VERSION "2027-draft-2026-10-23"

NS_ :

BS_:

BU_: BPS ElconInterface
VAL_TABLE_ EnableDisable 1 "Enabled" 0 "Disabled" ;
VAL_TABLE_ OnOff 1 "On" 0 "Off" ;
VAL_TABLE_ FaultState 1 "Fault" 0 "OK" ;
VAL_TABLE_ WarningState 1 "Warning" 0 "NoWarning" ;
VAL_TABLE_ DeviceStatus 2 "Waiting" 1 "Fault" 0 "OK" ;
VAL_TABLE_ Permission 1 "Allowed" 0 "NotAllowed" ;
VAL_TABLE_ Connection 1 "Connected" 0 "Disconnected" ;
VAL_TABLE_ BalancingMode 2 "Manual" 1 "Automatic" 0 "Off" ;
VAL_TABLE_ BalancingState 4 "BlockedOrFault" 3 "Complete" 2 "Paused" 1 "Balancing" 0 "Off" ;
VAL_TABLE_ BalancingBlockReason 7 "Other" 6 "BPSFault" 5 "Communication" 4 "VehicleState" 3 "CellVoltage" 2 "ChipTemperature" 1 "CellTemperature" 0 "None" ;
VAL_TABLE_ ServerConnection 1 "Connected" 0 "Disconnected/Retrying" ;
VAL_TABLE_ Pressed 1 "Pressed" 0 "NotPressed" ;
VAL_TABLE_ Validity 1 "Valid" 0 "Invalid" ;
VAL_TABLE_ Watchdog 1 "TimedOut" 0 "Alive" ;
VAL_TABLE_ NormalAdvanced 1 "Advanced" 0 "Normal" ;
VAL_TABLE_ MotorCommandSource 1 "External" 0 "VCU" ;
VAL_TABLE_ Gear 3 "Invalid" 2 "Reverse" 1 "Forward" 0 "Neutral" ;
VAL_TABLE_ BPSFaultSummary 5 "SMBFault" 4 "PrechargeFault" 3 "ContactorRelayFault" 2 "EmergencyStop" 1 "SetpointFault" 0 "OK" ;
VAL_TABLE_ VCUState 7 "VehicleNotReady" 6 "Disabled" 5 "CruiseControl" 4 "Regen" 3 "ReverseDrive" 2 "NeutralDrive" 1 "ForwardDrive" 0 "Init" ;
VAL_TABLE_ ChargeState 2 "Charging" 1 "Standby" 0 "Disabled" ;
VAL_TABLE_ EVSEState 5 "F_EVSEFault" 4 "E_Fault" 3 "D_VentilationRequired" 2 "C_ChargingReady" 1 "B_Connected" 0 "A_Disconnected" ;
VAL_TABLE_ GPSAntennaState 3 "Unknown" 2 "ShortCircuit" 1 "OpenCircuit" 0 "OK" ;
VAL_TABLE_ GPSFix 2 "Fix3D" 1 "Fix2D" 0 "NoFix" ;
VAL_TABLE_ CellularTechnology 4 "Other" 3 "NB_IoT" 2 "LTE_M" 1 "LTE" 0 "None" ;
VAL_TABLE_ TPEEControlMode 2 "ConstantInputVoltage" 1 "PerturbAndObserve" 0 "Disabled" ;
VAL_TABLE_ TPEEOperatingMode 7 "Fault" 6 "MinimumInputVoltage" 5 "TemperatureDerating" 4 "ConstantOutputCurrent" 3 "ConstantOutputVoltage" 2 "MinimumInputCurrent" 1 "ConstantInputCurrent" 0 "ConstantInputVoltage" ;
VAL_TABLE_ TPEEFault 8 "Fault" 7 "PhaseOverCurrent" 6 "InputUnderCurrent" 5 "InputOverCurrent" 4 "OutputOverCurrent" 3 "OutputOverVoltage" 2 "InputOverVoltage" 1 "ConfigurationError" 0 "OK" ;
VAL_TABLE_ LWSCalibration 1 "Calibrated" 0 "NotCalibrated" ;
VAL_TABLE_ LWSTrim 1 "Trimmed" 0 "NotTrimmed" ;
VAL_TABLE_ LWSCommand 5 "ResetCalibration" 3 "SetAngleZero" ;
VAL_TABLE_ ElconControl 1 "Disable" 0 "Charge" ;
VAL_TABLE_ ElconMuxPage 5 "Page5" 4 "Page4" 3 "Page3" 2 "Page2" 1 "Page1" ;

BO_ 121 BPSChargeData: 12 BPS
 SG_ CellSumVoltage : 0|12@1+ (0.05,0) [0|204.75] "V" Vector__XXX
 SG_ MainBatteryVoltage : 12|12@1+ (0.05,0) [0|204.75] "V" Vector__XXX
 SG_ MainVoltage : 24|12@1+ (0.05,0) [0|204.75] "V" Vector__XXX
 SG_ MinCellVoltage : 36|12@1+ (1,2000) [2000|6095] "mV" Vector__XXX
 SG_ MaxCellVoltage : 48|12@1+ (1,2000) [2000|6095] "mV" Vector__XXX
 SG_ MaxBatteryTemperature : 60|11@1+ (0.05,0) [0|102.35] "degC" Vector__XXX
 SG_ AverageBatteryTemperature : 71|11@1+ (0.05,0) [0|102.35] "degC" Vector__XXX
 SG_ BatteryCurrent : 82|14@1+ (0.01,-50) [-50|113.83] "A" Vector__XXX

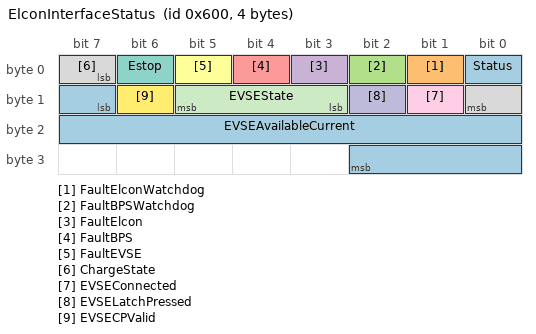
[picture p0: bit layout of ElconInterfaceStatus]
BO_ 1536 ElconInterfaceStatus: 4 ElconInterface
 SG_ Status : 0|1@1+ (1,0) [0.0|1.0] "" Vector__XXX
 SG_ FaultElconWatchdog : 1|1@1+ (1,0) [0.0|1.0] "" Vector__XXX
 SG_ FaultBPSWatchdog : 2|1@1+ (1,0) [0.0|1.0] "" Vector__XXX
 SG_ FaultElcon : 3|1@1+ (1,0) [0.0|1.0] "" Vector__XXX
 SG_ FaultBPS : 4|1@1+ (1,0) [0.0|1.0] "" Vector__XXX
 SG_ FaultEVSE : 5|1@1+ (1,0) [0.0|1.0] "" Vector__XXX
 SG_ Estop : 6|1@1+ (1,0) [0.0|1.0] "" Vector__XXX
 SG_ ChargeState : 7|2@1+ (1,0) [0.0|3.0] "" Vector__XXX
 SG_ EVSEConnected : 9|1@1+ (1,0) [0.0|1.0] "" Vector__XXX
 SG_ EVSELatchPressed : 10|1@1+ (1,0) [0.0|1.0] "" Vector__XXX
 SG_ EVSEState : 11|3@1+ (1,0) [0.0|7.0] "" Vector__XXX
 SG_ EVSECPValid : 14|1@1+ (1,0) [0.0|1.0] "" Vector__XXX
 SG_ EVSEAvailableCurrent : 15|12@1+ (0.01,0) [0|25.5] "A" Vector__XXX

CM_ BO_ 121 "Charging measurements from BPS at 10 Hz. MainBatteryVoltage and MainVoltage match BPSPackData; cell and temperature summaries match the CarCAN BPS data encodings.";
CM_ BO_ 1536 "2027 team-defined layout; physical values use the shared scaling conventions.";
CM_ SG_ 1536 EVSEAvailableCurrent "EVSEAvailableCurrent";
CM_ SG_ 1536 EVSECPValid "EVSECPValid";
CM_ SG_ 1536 EVSEState "EVSEState";
CM_ SG_ 1536 EVSELatchPressed "EVSELatchPressed";
CM_ SG_ 1536 EVSEConnected "EVSEConnected";
CM_ SG_ 1536 ChargeState "ChargeState";
CM_ SG_ 1536 Estop "Estop";
CM_ SG_ 1536 FaultEVSE "FaultEVSE";
CM_ SG_ 1536 FaultBPS "FaultBPS";
CM_ SG_ 1536 FaultElcon "FaultElcon";
CM_ SG_ 1536 FaultBPSWatchdog "FaultBPSWatchdog";
CM_ SG_ 1536 FaultElconWatchdog "FaultElconWatchdog";
CM_ SG_ 1536 Status "Status";
BA_DEF_ SG_  "ValueTable" STRING ;
BA_DEF_ BO_  "LayoutPending" INT 0 1;
BA_DEF_ BO_  "ProtocolSource" STRING ;
BA_DEF_  "BusType" STRING ;
BA_DEF_  "DBName" STRING ;
BA_DEF_ BO_  "VFrameFormat" ENUM  "StandardCAN","ExtendedCAN","reserved","J1939PG","reserved","reserved","reserved","reserved","reserved","reserved","reserved","reserved","reserved","reserved","StandardCAN_FD","ExtendedCAN_FD";
BA_DEF_ BO_  "CANFD_BRS" ENUM  "0","1";
BA_DEF_ BO_  "GenMsgSendType" ENUM  "Cyclic","Triggered","None";
BA_DEF_ BO_  "GenMsgCycleTime" INT 0 65535;
BA_DEF_  "DataBaudrate" INT 1 10000000;
BA_DEF_  "Baudrate" INT 1 10000000;
BA_DEF_DEF_  "ValueTable" "";
BA_DEF_DEF_  "LayoutPending" 0;
BA_DEF_DEF_  "ProtocolSource" "";
BA_DEF_DEF_  "BusType" "CAN";
BA_DEF_DEF_  "DBName" "";
BA_DEF_DEF_  "VFrameFormat" "StandardCAN";
BA_DEF_DEF_  "CANFD_BRS" "0";
BA_DEF_DEF_  "GenMsgSendType" "Cyclic";
BA_DEF_DEF_  "GenMsgCycleTime" 0;
BA_ "BusType" "CAN FD";
BA_ "DBName" "ChargerCAN";
BA_ "Baudrate" 500000;
BA_ "DataBaudrate" 500000;
BA_ "ProtocolSource" BO_ 121 "2027 allocation draft";
BA_ "VFrameFormat" BO_ 121 14;
BA_ "GenMsgCycleTime" BO_ 121 100;
BA_ "ProtocolSource" BO_ 1536 "2027 allocation draft";
BA_ "VFrameFormat" BO_ 1536 14;
BA_ "GenMsgCycleTime" BO_ 1536 100;
BA_ "ValueTable" SG_ 1536 EVSECPValid "Validity";
BA_ "ValueTable" SG_ 1536 EVSEState "EVSEState";
BA_ "ValueTable" SG_ 1536 EVSELatchPressed "Pressed";
BA_ "ValueTable" SG_ 1536 EVSEConnected "Connection";
BA_ "ValueTable" SG_ 1536 ChargeState "ChargeState";
BA_ "ValueTable" SG_ 1536 Estop "Pressed";
BA_ "ValueTable" SG_ 1536 FaultEVSE "FaultState";
BA_ "ValueTable" SG_ 1536 FaultBPS "FaultState";
BA_ "ValueTable" SG_ 1536 FaultElcon "FaultState";
BA_ "ValueTable" SG_ 1536 FaultBPSWatchdog "FaultState";
BA_ "ValueTable" SG_ 1536 FaultElconWatchdog "FaultState";
BA_ "ValueTable" SG_ 1536 Status "FaultState";
VAL_ 1536 EVSECPValid 0 "Invalid" 1 "Valid" ;
VAL_ 1536 EVSEState 0 "A_Disconnected" 1 "B_Connected" 2 "C_ChargingReady" 3 "D_VentilationRequired" 4 "E_Fault" 5 "F_EVSEFault" ;
VAL_ 1536 EVSELatchPressed 0 "NotPressed" 1 "Pressed" ;
VAL_ 1536 EVSEConnected 0 "Disconnected" 1 "Connected" ;
VAL_ 1536 ChargeState 0 "Disabled" 1 "Standby" 2 "Charging" ;
VAL_ 1536 Estop 0 "NotPressed" 1 "Pressed" ;
VAL_ 1536 FaultEVSE 0 "OK" 1 "Fault" ;
VAL_ 1536 FaultBPS 0 "OK" 1 "Fault" ;
VAL_ 1536 FaultElcon 0 "OK" 1 "Fault" ;
VAL_ 1536 FaultBPSWatchdog 0 "OK" 1 "Fault" ;
VAL_ 1536 FaultElconWatchdog 0 "OK" 1 "Fault" ;
VAL_ 1536 Status 0 "OK" 1 "Fault" ;
